AUTOSAR XML (schema 4-0-3)
package /PK_BB_Can_Network
  pdu Anchor1TpBle_A2M_Tp: length=64
  pdu Anchor1TpBle_M2A_Tp: length=64
  pdu Anchor2TpBle_A2M_Tp
  pdu Anchor3TpBle_A2M_Tp: length=64
  pdu Anchor4TpBle_A2M_Tp
  pdu Anchor5TpBle_A2M_Tp: length=64
  pdu Anchor6TpBle_A2M_Tp
  pdu Anchor7TpBle_A2M_Tp: length=64
  pdu Anchor8TpBle_A2M_Tp
  pdu Anchor9TpBle_A2M_Tp
  pdu Anchor{2..8}TpBle_M2A_Tp: length=64
  pdu Anchor9TpBle_M2A_Tp
  pdu Anchor{1..9}TpUwb_A2M_Tp: length=64
  pdu Anchor{1..9}TpUwb_M2A_Tp: length=64
  pdu TesterPhysical_Req_PK_Anchor{1..9}_Tp: length=64
  pdu TesterPhysical_Res_PK_Anchor{1..9}_Tp: length=64
  pdu TesterPhysical_Res_PK_MasterBle_Tp: length=64
  pdu TesterPhysical_Req_PK_MasterBle_Tp: length=64
  pdu TesterFunctional_Req_PK_Tp: length=64
  system PK_BB_Sys_Info
  i signal i pdu group MasterMcu_PK_BB_Rx: communication-direction=IN
    i-signal-i-pdus:
      Anchor{1..9}Hi_A2M
  i signal i pdu group MasterMcu_PK_BB_Tx: communication-direction=OUT, i-signal-i-pdus=MasterHi_M2A
package /PK_BB_Can_Network/Pkg_Cluster
  can cluster Can_Network_PK_BB: protocol-name=CAN
    can physical channel Can_Network_CHN_PK_BB: comm-connectors=Conn_Can_PK_BB_MasterEcu
      frame Anchor7Nm: id 0x477, to MasterMcu, frame-length=8, can-addressing-mode=STANDARD
        carries pdu Anchor7Nm: packing-byte-order=little-endian, start-position=0, update-indication-bit-position=-1
        nm pdu Anchor7Nm: length=8, nm-data-information=false, nm-vote-information=false
          signal WakeupReason_Anchor7: start 40, 8 bit, little-endian, base-type=uint8, to MasterMcu
          signal AutosarNMControlAnchor7: start 0, 8 bit, little-endian, init-value=0, base-type=uint8, compu {raw=phys for phys 0..255}, to MasterMcu  # SWS_CanNm_0045"
      frame Anchor6Nm: id 0x476, to MasterMcu, frame-length=8, can-addressing-mode=STANDARD
        carries pdu Anchor6Nm: packing-byte-order=little-endian, start-position=0, update-indication-bit-position=-1
        nm pdu Anchor6Nm: length=8, nm-data-information=false, nm-vote-information=false
          signal WakeupReason_Anchor6: start 40, 8 bit, little-endian, base-type=uint8, to MasterMcu
          signal AutosarNMControlAnchor6: start 0, 8 bit, little-endian, base-type=uint8, to MasterMcu  # SWS_CanNm_0045
      frame Anchor9TpBle_A2M: id 0x429, to MasterMcu, frame-length=64, can-addressing-mode=STANDARD
        carries pdu Anchor9TpBle_A2M: start-position=7, update-indication-bit-position=-1
        n pdu Anchor9TpBle_A2M: length=64
      frame Anchor8TpBle_A2M: id 0x428, to MasterMcu, frame-length=64, can-addressing-mode=STANDARD
        carries pdu Anchor8TpBle_A2M: start-position=7, update-indication-bit-position=-1
        n pdu Anchor8TpBle_A2M: length=64
      frame Anchor5Nm: id 0x475, to MasterMcu, frame-length=8, can-addressing-mode=STANDARD
        carries pdu Anchor5Nm: packing-byte-order=little-endian, start-position=0, update-indication-bit-position=-1
        nm pdu Anchor5Nm: length=8, nm-data-information=false, nm-vote-information=false
          signal WakeupReason_Anchor5: start 40, 8 bit, little-endian, base-type=uint8, to MasterMcu
          signal AutosarNMControlAnchor5: start 0, 8 bit, little-endian, base-type=uint8, to MasterMcu  # SWS_CanNm_0045
      frame Anchor4Nm: id 0x474, to MasterMcu, frame-length=8, can-addressing-mode=STANDARD
        carries pdu Anchor4Nm: packing-byte-order=little-endian, start-position=0, update-indication-bit-position=-1
        nm pdu Anchor4Nm: length=8, nm-data-information=false, nm-vote-information=false
          signal WakeupReason_Anchor4: start 40, 8 bit, little-endian, init-value=0, base-type=uint8, compu {raw=phys for phys 0..255, 0=NOWAKEUP, 1=NEWCONNECTIONREQUEST, 2=THRESHOLDCROSSED}, to MasterMcu
          signal AutosarNMControlAnchor4: start 0, 8 bit, little-endian, base-type=uint8, to MasterMcu  # SWS_CanNm_0045
      frame Anchor7TpBle_A2M: id 0x427, to MasterMcu, frame-length=64, can-addressing-mode=STANDARD
        carries pdu Anchor7TpBle_A2M: start-position=7, update-indication-bit-position=-1
        n pdu Anchor7TpBle_A2M: length=64
      frame Anchor6TpBle_A2M: id 0x426, to MasterMcu, frame-length=64, can-addressing-mode=STANDARD
        carries pdu Anchor6TpBle_A2M: start-position=7, update-indication-bit-position=-1
        n pdu Anchor6TpBle_A2M: length=64
      frame Anchor5TpBle_A2M: id 0x425, to MasterMcu, frame-length=64, can-addressing-mode=STANDARD
        carries pdu Anchor5TpBle_A2M: start-position=7, update-indication-bit-position=-1
        n pdu Anchor5TpBle_A2M: length=64
      frame Anchor4TpBle_A2M: id 0x424, to MasterMcu, frame-length=64, can-addressing-mode=STANDARD
        carries pdu Anchor4TpBle_A2M: start-position=7, update-indication-bit-position=-1
        n pdu Anchor4TpBle_A2M: length=64
      frame MasterBleXcpRequest: id 0x600, to MasterMcu, frame-length=8, can-addressing-mode=STANDARD
        carries pdu MasterBleXcpRequest: packing-byte-order=big-endian, start-position=7, update-indication-bit-position=-1
        pdu MasterBleXcpRequest: length=8, transmission-mode-condition{data-filter={data-filter-type=NEW-IS-WITHIN, max=2, min=0, offset=0}, i-signal-in-i-pdu=MasterBleXcpRequest}
          signal MasterBleXcpRequest: start 7, 64 bit, big-endian, base-type=uint64
      frame Anchor1Hi_A2M: id 0x161, to MasterMcu, frame-length=64, can-addressing-mode=STANDARD
        carries pdu Anchor1Hi_A2M: packing-byte-order=little-endian, start-position=0, update-indication-bit-position=-1
        pdu Anchor1Hi_A2M: length=64, transmission-mode-condition{data-filter={data-filter-type=NEW-IS-WITHIN, max=0, min=0, offset=0}, i-signal-in-i-pdu=Anchor1Hi_A2M_Payload}, transmission-mode-false-timing=cyclic-timing=time-period=0.1, transmission-mode-true-timing=cyclic-timing=time-period=0.1
          signal Anchor1Hi_A2M_Payload: start 0, 16 bit, little-endian, base-type=sint16, to MasterMcu
      frame Anchor3Nm: id 0x473, to MasterMcu, frame-length=8, can-addressing-mode=STANDARD
        carries pdu Anchor3Nm: packing-byte-order=little-endian, start-position=0, update-indication-bit-position=-1
        nm pdu Anchor3Nm: length=8, nm-data-information=false, nm-vote-information=false
          signal WakeupReason_Anchor3: start 40, 8 bit, little-endian, base-type=uint8, to MasterMcu
          signal AutosarNMControlAnchor3: start 0, 8 bit, little-endian, base-type=uint8, to MasterMcu  # SWS_CanNm_0045
      frame Anchor2Hi_A2M: id 0x162, to MasterMcu, frame-length=64, can-addressing-mode=STANDARD
        carries pdu Anchor2Hi_A2M: packing-byte-order=little-endian, start-position=0, update-indication-bit-position=-1
        pdu Anchor2Hi_A2M: length=64, transmission-mode-condition{data-filter={data-filter-type=NEW-IS-WITHIN, max=0, min=0, offset=0}, i-signal-in-i-pdu=Anchor2Hi_A2M_Payload}, transmission-mode-false-timing=cyclic-timing=time-period=0.1, transmission-mode-true-timing=cyclic-timing=time-period=0.1
          signal Anchor2Hi_A2M_Payload: start 0, 16 bit, little-endian, base-type=sint16, to MasterMcu
      frame Anchor2Nm: id 0x472, to MasterMcu, frame-length=8, can-addressing-mode=STANDARD
        carries pdu Anchor2Nm: packing-byte-order=little-endian, start-position=0, update-indication-bit-position=-1
        nm pdu Anchor2Nm: length=8, nm-data-information=false, nm-vote-information=false
          signal WakeupReason_Anchor2: start 40, 8 bit, little-endian, base-type=uint8, to MasterMcu
          signal AutosarNMControlAnchor2: start 0, 8 bit, little-endian, base-type=uint8, to MasterMcu  # SWS_CanNm_0045
      frame Anchor1Nm: id 0x471, to MasterMcu, frame-length=8, can-addressing-mode=STANDARD
        carries pdu Anchor1Nm: packing-byte-order=little-endian, start-position=0, update-indication-bit-position=-1
        nm pdu Anchor1Nm: length=8, nm-data-information=false, nm-vote-information=false
          signal WakeupReason_Anchor1: start 40, 8 bit, little-endian, init-value=0, base-type=uint8, compu {raw=phys for phys 0..255, 0=NOWAKEUP, 1=NEWCONNECTIONREQUEST, 2=THRESHOLDCROSSED}, to MasterMcu
          signal AutosarNMControlAnchor1: start 0, 8 bit, little-endian, base-type=uint8, to MasterMcu  # SWS_CanNm_0045
      frame Anchor3Hi_A2M: id 0x163, to MasterMcu, frame-length=64, can-addressing-mode=STANDARD
        carries pdu Anchor3Hi_A2M: packing-byte-order=little-endian, start-position=0, update-indication-bit-position=-1
        pdu Anchor3Hi_A2M: length=64, transmission-mode-condition{data-filter={data-filter-type=NEW-IS-WITHIN, max=0, min=0, offset=0}, i-signal-in-i-pdu=Anchor3Hi_A2M_Payload}, transmission-mode-false-timing=cyclic-timing=time-period=0.1, transmission-mode-true-timing=cyclic-timing=time-period=0.1
          signal Anchor3Hi_A2M_Payload: start 0, 16 bit, little-endian, init-value=0, base-type=sint16, compu {raw=phys for phys 0}, to MasterMcu
      frame Anchor3TpBle_A2M: id 0x423, to MasterMcu, frame-length=64, can-addressing-mode=STANDARD
        carries pdu Anchor3TpBle_A2M: start-position=7, update-indication-bit-position=-1
        n pdu Anchor3TpBle_A2M: length=64
      frame Anchor4Hi_A2M: id 0x164, to MasterMcu, frame-length=64, can-addressing-mode=STANDARD
        carries pdu Anchor4Hi_A2M: packing-byte-order=little-endian, start-position=0, update-indication-bit-position=-1
        pdu Anchor4Hi_A2M: length=64, transmission-mode-condition{data-filter={data-filter-type=NEW-IS-WITHIN, max=0, min=0, offset=0}, i-signal-in-i-pdu=Anchor4Hi_A2M_Payload}
          signal Anchor4Hi_A2M_Payload: start 0, 16 bit, little-endian, base-type=sint16, to MasterMcu
      frame Anchor2TpBle_A2M: id 0x422, to MasterMcu, frame-length=64, can-addressing-mode=STANDARD
        carries pdu Anchor2TpBle_A2M: start-position=7, update-indication-bit-position=-1
        n pdu Anchor2TpBle_A2M: length=64
      frame Anchor5Hi_A2M: id 0x165, to MasterMcu, frame-length=64, can-addressing-mode=STANDARD
        carries pdu Anchor5Hi_A2M: packing-byte-order=little-endian, start-position=0, update-indication-bit-position=-1
        pdu Anchor5Hi_A2M: length=64, transmission-mode-condition{data-filter={data-filter-type=NEW-IS-WITHIN, max=0, min=0, offset=0}, i-signal-in-i-pdu=Anchor5Hi_A2M_Payload}
          signal Anchor5Hi_A2M_Payload: start 0, 16 bit, little-endian, init-value=0, base-type=sint16, compu {raw=phys for phys 0}, to MasterMcu
      frame Anchor1TpBle_A2M: id 0x421, to MasterMcu, frame-length=64, can-addressing-mode=STANDARD
        carries pdu Anchor1TpBle_A2M: start-position=7, update-indication-bit-position=-1
        n pdu Anchor1TpBle_A2M: length=64
      frame Anchor6Hi_A2M: id 0x166, to MasterMcu, frame-length=64, can-addressing-mode=STANDARD
        carries pdu Anchor6Hi_A2M: packing-byte-order=little-endian, start-position=0, update-indication-bit-position=-1
        pdu Anchor6Hi_A2M: length=64, transmission-mode-condition{data-filter={data-filter-type=NEW-IS-WITHIN, max=0, min=0, offset=0}, i-signal-in-i-pdu=Anchor6Hi_A2M_Payload}
          signal Anchor6Hi_A2M_Payload: start 0, 16 bit, little-endian, init-value=0, base-type=sint16, compu {raw=phys for phys 0}, to MasterMcu
      frame Anchor7Hi_A2M: id 0x167, to MasterMcu, frame-length=64, can-addressing-mode=STANDARD
        carries pdu Anchor7Hi_A2M: packing-byte-order=little-endian, start-position=0, update-indication-bit-position=-1
        pdu Anchor7Hi_A2M: length=64, transmission-mode-condition{data-filter={data-filter-type=NEW-IS-WITHIN, max=0, min=0, offset=0}, i-signal-in-i-pdu=Anchor7Hi_A2M_Payload}, transmission-mode-false-timing=cyclic-timing=time-period=0.1, transmission-mode-true-timing=cyclic-timing=time-period=0.1
          signal Anchor7Hi_A2M_Payload: start 0, 16 bit, little-endian, base-type=sint16, to MasterMcu
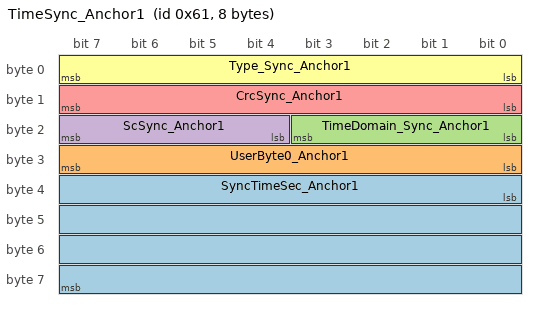
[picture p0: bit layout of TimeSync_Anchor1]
      frame TimeSync_Anchor1: id 0x61, to MasterMcu, frame-length=8, can-addressing-mode=STANDARD
        carries pdu TimeSync_Anchor1: packing-byte-order=little-endian, start-position=0, update-indication-bit-position=-1
        pdu TimeSync_Anchor1: length=8, transmission-mode-false-timing=cyclic-timing={time-offset=0.0, time-period=5.0}, transmission-mode-true-timing=cyclic-timing={time-offset=0.0, time-period=5.0}
          transmission-mode-conditions:
            {data-filter={data-filter-type=NEW-IS-WITHIN, max=4294967295, min=0, offset=0}, i-signal-in-i-pdu=SyncTimeSec_Anchor1}
            {data-filter={data-filter-type=ALWAYS, max=255, min=0, offset=0}, i-signal-in-i-pdu=UserByte0_Anchor1}
            {data-filter={data-filter-type=ALWAYS, max=15, min=0, offset=0}, i-signal-in-i-pdu=TimeDomain_Sync_Anchor1}
            {data-filter={data-filter-type=ALWAYS, max=15, min=0, offset=0}, i-signal-in-i-pdu=ScSync_Anchor1}
            {data-filter={data-filter-type=ALWAYS, max=255, min=0, offset=0}, i-signal-in-i-pdu=CrcSync_Anchor1}
            {data-filter={data-filter-type=ALWAYS, max=255, min=0, offset=0}, i-signal-in-i-pdu=Type_Sync_Anchor1}
          signal SyncTimeSec_Anchor1: start 32, 32 bit, little-endian, base-type=uint32, to MasterMcu
          signal UserByte0_Anchor1: start 24, 8 bit, little-endian, base-type=uint8, to MasterMcu
          signal TimeDomain_Sync_Anchor1: start 16, 4 bit, little-endian, base-type=uint8, to MasterMcu
          signal ScSync_Anchor1: start 20, 4 bit, little-endian, base-type=uint8, to MasterMcu
          signal CrcSync_Anchor1: start 8, 8 bit, little-endian, base-type=uint8, to MasterMcu
          signal Type_Sync_Anchor1: start 0, 8 bit, little-endian, init-value=32, base-type=uint8, compu {raw=phys for phys 0..255}, to MasterMcu
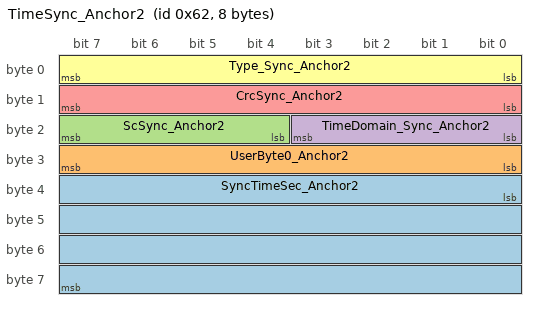
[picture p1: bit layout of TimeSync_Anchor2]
      frame TimeSync_Anchor2: id 0x62, to MasterMcu, frame-length=8, can-addressing-mode=STANDARD
        carries pdu TimeSync_Anchor2: packing-byte-order=little-endian, start-position=0, update-indication-bit-position=-1
        pdu TimeSync_Anchor2: length=8, transmission-mode-false-timing=cyclic-timing={time-offset=0.0, time-period=5.0}, transmission-mode-true-timing=cyclic-timing={time-offset=0.0, time-period=5.0}
          transmission-mode-conditions:
            {data-filter={data-filter-type=NEW-IS-WITHIN, max=4294967295, min=0, offset=0}, i-signal-in-i-pdu=SyncTimeSec_Anchor2}
            {data-filter={data-filter-type=ALWAYS, max=255, min=0, offset=0}, i-signal-in-i-pdu=UserByte0_Anchor2}
            {data-filter={data-filter-type=ALWAYS, max=15, min=0, offset=0}, i-signal-in-i-pdu=ScSync_Anchor2}
            {data-filter={data-filter-type=ALWAYS, max=15, min=0, offset=0}, i-signal-in-i-pdu=TimeDomain_Sync_Anchor2}
            {data-filter={data-filter-type=ALWAYS, max=255, min=0, offset=0}, i-signal-in-i-pdu=CrcSync_Anchor2}
            {data-filter={data-filter-type=ALWAYS, max=255, min=0, offset=0}, i-signal-in-i-pdu=Type_Sync_Anchor2}
          signal SyncTimeSec_Anchor2: start 32, 32 bit, little-endian, init-value=0, base-type=uint32, compu {raw=phys for phys 0..4294967295}, to MasterMcu
          signal UserByte0_Anchor2: start 24, 8 bit, little-endian, init-value=0, base-type=uint8, compu {raw=phys for phys 0..255}, to MasterMcu
          signal ScSync_Anchor2: start 20, 4 bit, little-endian, base-type=uint8, to MasterMcu
          signal TimeDomain_Sync_Anchor2: start 16, 4 bit, little-endian, base-type=uint8, to MasterMcu
          signal CrcSync_Anchor2: start 8, 8 bit, little-endian, init-value=0, base-type=uint8, compu {raw=phys for phys 0..255}, to MasterMcu
          signal Type_Sync_Anchor2: start 0, 8 bit, little-endian, base-type=uint8, to MasterMcu
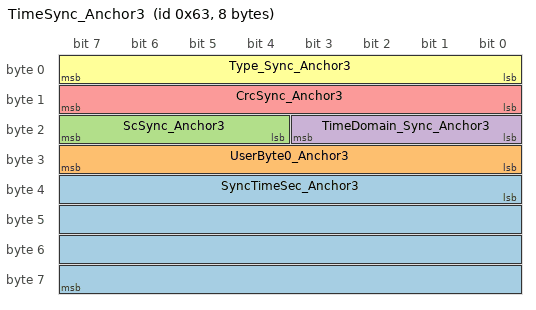
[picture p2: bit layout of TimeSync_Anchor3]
      frame TimeSync_Anchor3: id 0x63, to MasterMcu, frame-length=8, can-addressing-mode=STANDARD
        carries pdu TimeSync_Anchor3: packing-byte-order=little-endian, start-position=0, update-indication-bit-position=-1
        pdu TimeSync_Anchor3: length=8, transmission-mode-false-timing=cyclic-timing={time-offset=0.0, time-period=5.0}, transmission-mode-true-timing=cyclic-timing={time-offset=0.0, time-period=5.0}
          transmission-mode-conditions:
            {data-filter={data-filter-type=NEW-IS-WITHIN, max=4294967295, min=0, offset=0}, i-signal-in-i-pdu=SyncTimeSec_Anchor3}
            {data-filter={data-filter-type=ALWAYS, max=255, min=0, offset=0}, i-signal-in-i-pdu=UserByte0_Anchor3}
            {data-filter={data-filter-type=ALWAYS, max=15, min=0, offset=0}, i-signal-in-i-pdu=ScSync_Anchor3}
            {data-filter={data-filter-type=ALWAYS, max=15, min=0, offset=0}, i-signal-in-i-pdu=TimeDomain_Sync_Anchor3}
            {data-filter={data-filter-type=ALWAYS, max=255, min=0, offset=0}, i-signal-in-i-pdu=CrcSync_Anchor3}
            {data-filter={data-filter-type=ALWAYS, max=255, min=0, offset=0}, i-signal-in-i-pdu=Type_Sync_Anchor3}
          signal SyncTimeSec_Anchor3: start 32, 32 bit, little-endian, base-type=uint32, to MasterMcu
          signal UserByte0_Anchor3: start 24, 8 bit, little-endian, base-type=uint8, to MasterMcu
          signal ScSync_Anchor3: start 20, 4 bit, little-endian, init-value=0, base-type=uint8, compu {raw=phys for phys 0..15}, to MasterMcu
          signal TimeDomain_Sync_Anchor3: start 16, 4 bit, little-endian, base-type=uint8, to MasterMcu
          signal CrcSync_Anchor3: start 8, 8 bit, little-endian, base-type=uint8, to MasterMcu
          signal Type_Sync_Anchor3: start 0, 8 bit, little-endian, base-type=uint8, to MasterMcu
      frame TesterPhysical_Req_PK_MasterBle: id 0x700, to MasterMcu, frame-length=64, can-addressing-mode=STANDARD
        carries pdu TesterPhysical_Req_PK_MasterBle: start-position=7, update-indication-bit-position=-1
        n pdu TesterPhysical_Req_PK_MasterBle: length=64
      frame Anchor8Hi_A2M: id 0x168, to MasterMcu, frame-length=64, can-addressing-mode=STANDARD
        carries pdu Anchor8Hi_A2M: packing-byte-order=little-endian, start-position=0, update-indication-bit-position=-1
        pdu Anchor8Hi_A2M: length=64, transmission-mode-condition{data-filter={data-filter-type=NEW-IS-WITHIN, max=0, min=0, offset=0}, i-signal-in-i-pdu=Anchor8Hi_A2M_Payload}
          signal Anchor8Hi_A2M_Payload: start 0, 16 bit, little-endian, base-type=sint16, to MasterMcu
      frame Anchor9Hi_A2M: id 0x169, to MasterMcu, frame-length=64, can-addressing-mode=STANDARD
        carries pdu Anchor9Hi_A2M: packing-byte-order=little-endian, start-position=0, update-indication-bit-position=-1
        pdu Anchor9Hi_A2M: length=64, transmission-mode-condition{data-filter={data-filter-type=NEW-IS-WITHIN, max=0, min=0, offset=0}, i-signal-in-i-pdu=Anchor9Hi_A2M_Payload}, transmission-mode-false-timing=cyclic-timing=time-period=0.1, transmission-mode-true-timing=cyclic-timing=time-period=0.1
          signal Anchor9Hi_A2M_Payload: start 0, 16 bit, little-endian, base-type=sint16, to MasterMcu
      frame Anchor9Nm: id 0x479, to MasterMcu, frame-length=8, can-addressing-mode=STANDARD
        carries pdu Anchor9Nm: packing-byte-order=little-endian, start-position=0, update-indication-bit-position=-1
        nm pdu Anchor9Nm: length=8, nm-data-information=false, nm-vote-information=false
          signal WakeupReason_Anchor9: start 40, 8 bit, little-endian, init-value=0, base-type=uint8, compu {raw=phys for phys 0..255, 0=NOWAKEUP, 1=NEWCONNECTIONREQUEST, 2=THRESHOLDCROSSED}, to MasterMcu
          signal AutosarNMControlAnchor9: start 0, 8 bit, little-endian, base-type=uint8, to MasterMcu  # SWS_CanNm_0045
      frame Anchor8Nm: id 0x478, to MasterMcu, frame-length=8, can-addressing-mode=STANDARD
        carries pdu Anchor8Nm: packing-byte-order=little-endian, start-position=0, update-indication-bit-position=-1
        nm pdu Anchor8Nm: length=8, nm-data-information=false, nm-vote-information=false
          signal WakeupReason_Anchor8: start 40, 8 bit, little-endian, base-type=uint8, to MasterMcu
          signal AutosarNMControlAnchor8: start 0, 8 bit, little-endian, init-value=0, base-type=uint8, compu {raw=phys for phys 0..255}, to MasterMcu  # SWS_CanNm_0045"
      frame TesterPhysical_Res_PK_Anchor5: id 0x725, to MasterMcu, frame-length=64, can-addressing-mode=STANDARD
        carries pdu TesterPhysical_Res_PK_Anchor5: start-position=7, update-indication-bit-position=-1
        n pdu TesterPhysical_Res_PK_Anchor5: length=64
      frame TesterPhysical_Res_PK_Anchor4: id 0x724, to MasterMcu, frame-length=64, can-addressing-mode=STANDARD
        carries pdu TesterPhysical_Res_PK_Anchor4: start-position=7, update-indication-bit-position=-1
        n pdu TesterPhysical_Res_PK_Anchor4: length=64
      frame TesterPhysical_Res_PK_Anchor3: id 0x723, to MasterMcu, frame-length=64, can-addressing-mode=STANDARD
        carries pdu TesterPhysical_Res_PK_Anchor3: start-position=7, update-indication-bit-position=-1
        n pdu TesterPhysical_Res_PK_Anchor3: length=64
      frame TesterPhysical_Res_PK_Anchor2: id 0x722, to MasterMcu, frame-length=64, can-addressing-mode=STANDARD
        carries pdu TesterPhysical_Res_PK_Anchor2: start-position=7, update-indication-bit-position=-1
        n pdu TesterPhysical_Res_PK_Anchor2: length=64
      frame TesterPhysical_Res_PK_Anchor1: id 0x721, to MasterMcu, frame-length=64, can-addressing-mode=STANDARD
        carries pdu TesterPhysical_Res_PK_Anchor1: start-position=7, update-indication-bit-position=-1
        n pdu TesterPhysical_Res_PK_Anchor1: length=64
      frame Anchor1TpUwb_A2M: id 0x461, to MasterMcu, frame-length=64, can-addressing-mode=STANDARD
        carries pdu Anchor1TpUwb_A2M: start-position=7, update-indication-bit-position=-1
        n pdu Anchor1TpUwb_A2M: length=64
      frame TesterPhysical_Res_PK_Anchor9: id 0x729, to MasterMcu, frame-length=64, can-addressing-mode=STANDARD
        carries pdu TesterPhysical_Res_PK_Anchor9: start-position=7, update-indication-bit-position=-1
        n pdu TesterPhysical_Res_PK_Anchor9: length=64
      frame TesterPhysical_Res_PK_Anchor8: id 0x728, to MasterMcu, frame-length=64, can-addressing-mode=STANDARD
        carries pdu TesterPhysical_Res_PK_Anchor8: start-position=7, update-indication-bit-position=-1
        n pdu TesterPhysical_Res_PK_Anchor8: length=64
      frame TesterPhysical_Res_PK_Anchor7: id 0x727, to MasterMcu, frame-length=64, can-addressing-mode=STANDARD
        carries pdu TesterPhysical_Res_PK_Anchor7: start-position=7, update-indication-bit-position=-1
        n pdu TesterPhysical_Res_PK_Anchor7: length=64
      frame TesterPhysical_Res_PK_Anchor6: id 0x726, to MasterMcu, frame-length=64, can-addressing-mode=STANDARD
        carries pdu TesterPhysical_Res_PK_Anchor6: start-position=7, update-indication-bit-position=-1
        n pdu TesterPhysical_Res_PK_Anchor6: length=64
      frame Anchor9TpUwb_A2M: id 0x469, to MasterMcu, frame-length=64, can-addressing-mode=STANDARD
        carries pdu Anchor9TpUwb_A2M: start-position=7, update-indication-bit-position=-1
        n pdu Anchor9TpUwb_A2M: length=64
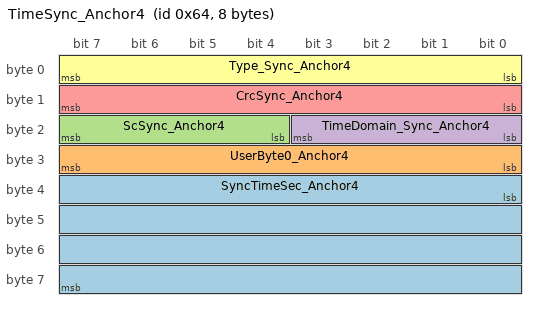
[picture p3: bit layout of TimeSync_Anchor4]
      frame TimeSync_Anchor4: id 0x64, to MasterMcu, frame-length=8, can-addressing-mode=STANDARD
        carries pdu TimeSync_Anchor4: packing-byte-order=little-endian, start-position=0, update-indication-bit-position=-1
        pdu TimeSync_Anchor4: length=8, transmission-mode-false-timing=cyclic-timing={time-offset=0.0, time-period=5.0}, transmission-mode-true-timing=cyclic-timing={time-offset=0.0, time-period=5.0}
          transmission-mode-conditions:
            {data-filter={data-filter-type=NEW-IS-WITHIN, max=4294967295, min=0, offset=0}, i-signal-in-i-pdu=SyncTimeSec_Anchor4}
            {data-filter={data-filter-type=ALWAYS, max=255, min=0, offset=0}, i-signal-in-i-pdu=UserByte0_Anchor4}
            {data-filter={data-filter-type=ALWAYS, max=15, min=0, offset=0}, i-signal-in-i-pdu=ScSync_Anchor4}
            {data-filter={data-filter-type=ALWAYS, max=15, min=0, offset=0}, i-signal-in-i-pdu=TimeDomain_Sync_Anchor4}
            {data-filter={data-filter-type=ALWAYS, max=255, min=0, offset=0}, i-signal-in-i-pdu=CrcSync_Anchor4}
            {data-filter={data-filter-type=ALWAYS, max=255, min=0, offset=0}, i-signal-in-i-pdu=Type_Sync_Anchor4}
          signal SyncTimeSec_Anchor4: start 32, 32 bit, little-endian, base-type=uint32, to MasterMcu
          signal UserByte0_Anchor4: start 24, 8 bit, little-endian, base-type=uint8, to MasterMcu
          signal ScSync_Anchor4: start 20, 4 bit, little-endian, base-type=uint8, to MasterMcu
          signal TimeDomain_Sync_Anchor4: start 16, 4 bit, little-endian, base-type=uint8, to MasterMcu
          signal CrcSync_Anchor4: start 8, 8 bit, little-endian, base-type=uint8, to MasterMcu
          signal Type_Sync_Anchor4: start 0, 8 bit, little-endian, base-type=uint8, to MasterMcu
      frame Anchor8TpUwb_A2M: id 0x468, to MasterMcu, frame-length=64, can-addressing-mode=STANDARD
        carries pdu Anchor8TpUwb_A2M: start-position=7, update-indication-bit-position=-1
        n pdu Anchor8TpUwb_A2M: length=64
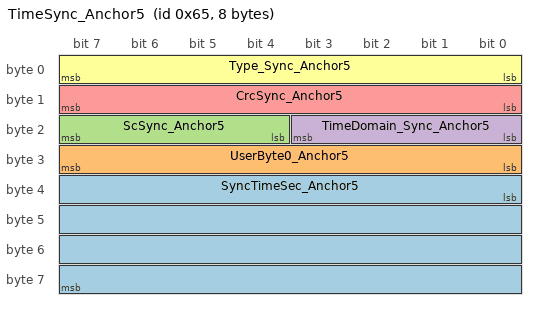
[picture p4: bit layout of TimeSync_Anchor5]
      frame TimeSync_Anchor5: id 0x65, to MasterMcu, frame-length=8, can-addressing-mode=STANDARD
        carries pdu TimeSync_Anchor5: packing-byte-order=little-endian, start-position=0, update-indication-bit-position=-1
        pdu TimeSync_Anchor5: length=8, transmission-mode-false-timing=cyclic-timing={time-offset=0.0, time-period=5.0}, transmission-mode-true-timing=cyclic-timing={time-offset=0.0, time-period=5.0}
          transmission-mode-conditions:
            {data-filter={data-filter-type=NEW-IS-WITHIN, max=4294967295, min=0, offset=0}, i-signal-in-i-pdu=SyncTimeSec_Anchor5}
            {data-filter={data-filter-type=ALWAYS, max=255, min=0, offset=0}, i-signal-in-i-pdu=UserByte0_Anchor5}
            {data-filter={data-filter-type=ALWAYS, max=15, min=0, offset=0}, i-signal-in-i-pdu=ScSync_Anchor5}
            {data-filter={data-filter-type=ALWAYS, max=15, min=0, offset=0}, i-signal-in-i-pdu=TimeDomain_Sync_Anchor5}
            {data-filter={data-filter-type=ALWAYS, max=255, min=0, offset=0}, i-signal-in-i-pdu=CrcSync_Anchor5}
            {data-filter={data-filter-type=ALWAYS, max=255, min=0, offset=0}, i-signal-in-i-pdu=Type_Sync_Anchor5}
          signal SyncTimeSec_Anchor5: start 32, 32 bit, little-endian, base-type=uint32, to MasterMcu
          signal UserByte0_Anchor5: start 24, 8 bit, little-endian, base-type=uint8, to MasterMcu
          signal ScSync_Anchor5: start 20, 4 bit, little-endian, init-value=0, base-type=uint8, compu {raw=phys for phys 0..15}, to MasterMcu
          signal TimeDomain_Sync_Anchor5: start 16, 4 bit, little-endian, base-type=uint8, to MasterMcu
          signal CrcSync_Anchor5: start 8, 8 bit, little-endian, base-type=uint8, to MasterMcu
          signal Type_Sync_Anchor5: start 0, 8 bit, little-endian, init-value=0, base-type=uint8, compu {raw=phys for phys 0..255}, to MasterMcu
      frame MasterUwbXcpRequest: id 0x640, to MasterMcu, frame-length=8, can-addressing-mode=STANDARD
        carries pdu MasterUwbXcpRequest: packing-byte-order=big-endian, start-position=7, update-indication-bit-position=-1
        pdu MasterUwbXcpRequest: length=8, transmission-mode-condition{data-filter={data-filter-type=NEW-IS-WITHIN, max=2, min=0, offset=0}, i-signal-in-i-pdu=MasterUwbXcpRequest}
          signal MasterUwbXcpRequest: start 7, 64 bit, big-endian, init-value=0, base-type=uint64, compu {raw=phys for phys 0..1.8446744}
      frame Anchor7TpUwb_A2M: id 0x467, to MasterMcu, frame-length=64, can-addressing-mode=STANDARD
        carries pdu Anchor7TpUwb_A2M: start-position=7, update-indication-bit-position=-1
        n pdu Anchor7TpUwb_A2M: length=64
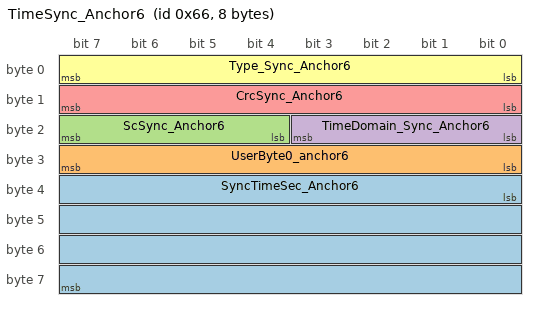
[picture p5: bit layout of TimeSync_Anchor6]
      frame TimeSync_Anchor6: id 0x66, to MasterMcu, frame-length=8, can-addressing-mode=STANDARD
        carries pdu TimeSync_Anchor6: packing-byte-order=little-endian, start-position=0, update-indication-bit-position=-1
        pdu TimeSync_Anchor6: length=8, transmission-mode-false-timing=cyclic-timing={time-offset=0.0, time-period=5.0}, transmission-mode-true-timing=cyclic-timing={time-offset=0.0, time-period=5.0}
          transmission-mode-conditions:
            {data-filter={data-filter-type=NEW-IS-WITHIN, max=4294967295, min=0, offset=0}, i-signal-in-i-pdu=SyncTimeSec_Anchor6}
            {data-filter={data-filter-type=ALWAYS, max=255, min=0, offset=0}, i-signal-in-i-pdu=UserByte0_anchor6}
            {data-filter={data-filter-type=ALWAYS, max=15, min=0, offset=0}, i-signal-in-i-pdu=ScSync_Anchor6}
            {data-filter={data-filter-type=ALWAYS, max=15, min=0, offset=0}, i-signal-in-i-pdu=TimeDomain_Sync_Anchor6}
            {data-filter={data-filter-type=ALWAYS, max=255, min=0, offset=0}, i-signal-in-i-pdu=CrcSync_Anchor6}
            {data-filter={data-filter-type=ALWAYS, max=255, min=0, offset=0}, i-signal-in-i-pdu=Type_Sync_Anchor6}
          signal SyncTimeSec_Anchor6: start 32, 32 bit, little-endian, base-type=uint32, to MasterMcu
          signal UserByte0_anchor6: start 24, 8 bit, little-endian, base-type=uint8, to MasterMcu
          signal ScSync_Anchor6: start 20, 4 bit, little-endian, init-value=0, base-type=uint8, compu {raw=phys for phys 0..15}, to MasterMcu
          signal TimeDomain_Sync_Anchor6: start 16, 4 bit, little-endian, init-value=0, base-type=uint8, compu {raw=phys for phys 0..15}, to MasterMcu
          signal CrcSync_Anchor6: start 8, 8 bit, little-endian, base-type=uint8, to MasterMcu
          signal Type_Sync_Anchor6: start 0, 8 bit, little-endian, base-type=uint8, to MasterMcu
      frame Anchor6TpUwb_A2M: id 0x466, to MasterMcu, frame-length=64, can-addressing-mode=STANDARD
        carries pdu Anchor6TpUwb_A2M: start-position=7, update-indication-bit-position=-1
        n pdu Anchor6TpUwb_A2M: length=64
      frame Anchor5TpUwb_A2M: id 0x465, to MasterMcu, frame-length=64, can-addressing-mode=STANDARD
        carries pdu Anchor5TpUwb_A2M: start-position=7, update-indication-bit-position=-1
        n pdu Anchor5TpUwb_A2M: length=64
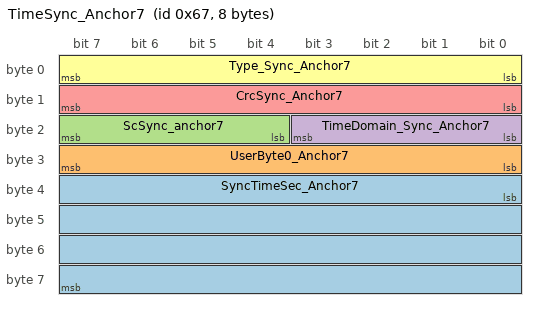
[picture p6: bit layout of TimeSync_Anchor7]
      frame TimeSync_Anchor7: id 0x67, to MasterMcu, frame-length=8, can-addressing-mode=STANDARD
        carries pdu TimeSync_Anchor7: packing-byte-order=little-endian, start-position=0, update-indication-bit-position=-1
        pdu TimeSync_Anchor7: length=8, transmission-mode-false-timing=cyclic-timing={time-offset=0.0, time-period=5.0}, transmission-mode-true-timing=cyclic-timing={time-offset=0.0, time-period=5.0}
          transmission-mode-conditions:
            {data-filter={data-filter-type=NEW-IS-WITHIN, max=4294967295, min=0, offset=0}, i-signal-in-i-pdu=SyncTimeSec_Anchor7}
            {data-filter={data-filter-type=ALWAYS, max=255, min=0, offset=0}, i-signal-in-i-pdu=UserByte0_Anchor7}
            {data-filter={data-filter-type=ALWAYS, max=15, min=0, offset=0}, i-signal-in-i-pdu=ScSync_anchor7}
            {data-filter={data-filter-type=ALWAYS, max=15, min=0, offset=0}, i-signal-in-i-pdu=TimeDomain_Sync_Anchor7}
            {data-filter={data-filter-type=ALWAYS, max=255, min=0, offset=0}, i-signal-in-i-pdu=CrcSync_Anchor7}
            {data-filter={data-filter-type=ALWAYS, max=255, min=0, offset=0}, i-signal-in-i-pdu=Type_Sync_Anchor7}
          signal SyncTimeSec_Anchor7: start 32, 32 bit, little-endian, base-type=uint32, to MasterMcu
          signal UserByte0_Anchor7: start 24, 8 bit, little-endian, init-value=0, base-type=uint8, compu {raw=phys for phys 0..255}, to MasterMcu
          signal ScSync_anchor7: start 20, 4 bit, little-endian, base-type=uint8, to MasterMcu
          signal TimeDomain_Sync_Anchor7: start 16, 4 bit, little-endian, init-value=0, base-type=uint8, compu {raw=phys for phys 0..15}, to MasterMcu
          signal CrcSync_Anchor7: start 8, 8 bit, little-endian, base-type=uint8, to MasterMcu
          signal Type_Sync_Anchor7: start 0, 8 bit, little-endian, init-value=32, base-type=uint8, compu {raw=phys for phys 0..255}, to MasterMcu
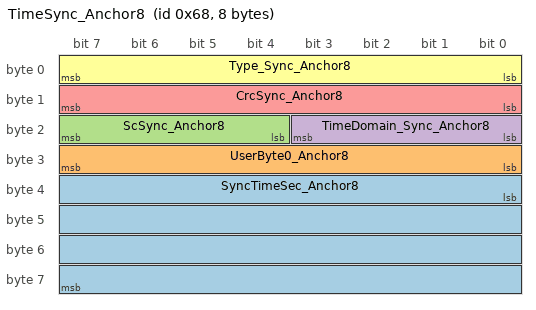
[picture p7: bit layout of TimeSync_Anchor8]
      frame TimeSync_Anchor8: id 0x68, to MasterMcu, frame-length=8, can-addressing-mode=STANDARD
        carries pdu TimeSync_Anchor8: packing-byte-order=little-endian, start-position=0, update-indication-bit-position=-1
        pdu TimeSync_Anchor8: length=8, transmission-mode-false-timing=cyclic-timing={time-offset=0.0, time-period=5.0}, transmission-mode-true-timing=cyclic-timing={time-offset=0.0, time-period=5.0}
          transmission-mode-conditions:
            {data-filter={data-filter-type=NEW-IS-WITHIN, max=4294967295, min=0, offset=0}, i-signal-in-i-pdu=SyncTimeSec_Anchor8}
            {data-filter={data-filter-type=ALWAYS, max=255, min=0, offset=0}, i-signal-in-i-pdu=UserByte0_Anchor8}
            {data-filter={data-filter-type=ALWAYS, max=15, min=0, offset=0}, i-signal-in-i-pdu=TimeSync_Anchor8/ScSync_Anchor8}
            {data-filter={data-filter-type=ALWAYS, max=15, min=0, offset=0}, i-signal-in-i-pdu=TimeDomain_Sync_Anchor8}
            {data-filter={data-filter-type=ALWAYS, max=255, min=0, offset=0}, i-signal-in-i-pdu=CrcSync_Anchor8}
            {data-filter={data-filter-type=ALWAYS, max=255, min=0, offset=0}, i-signal-in-i-pdu=Type_Sync_Anchor8}
          signal SyncTimeSec_Anchor8: start 32, 32 bit, little-endian, base-type=uint32, to MasterMcu
          signal UserByte0_Anchor8: start 24, 8 bit, little-endian, base-type=uint8, to MasterMcu
          signal ScSync_Anchor8: start 20, 4 bit, little-endian, base-type=uint8, to MasterMcu
          signal TimeDomain_Sync_Anchor8: start 16, 4 bit, little-endian, init-value=0, base-type=uint8, compu {raw=phys for phys 0..15}, to MasterMcu
          signal CrcSync_Anchor8: start 8, 8 bit, little-endian, init-value=0, base-type=uint8, compu {raw=phys for phys 0..255}, to MasterMcu
          signal Type_Sync_Anchor8: start 0, 8 bit, little-endian, init-value=32, base-type=uint8, compu {raw=phys for phys 0..255}, to MasterMcu
      frame Anchor4TpUwb_A2M: id 0x464, to MasterMcu, frame-length=64, can-addressing-mode=STANDARD
        carries pdu Anchor4TpUwb_A2M: start-position=7, update-indication-bit-position=-1
        n pdu Anchor4TpUwb_A2M: length=64
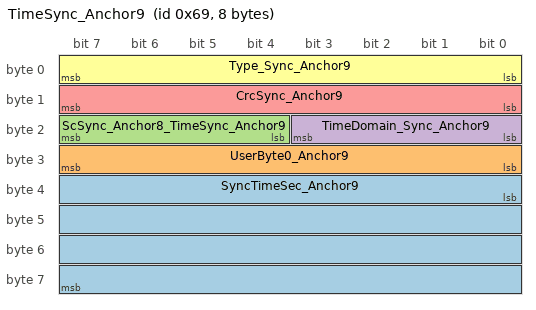
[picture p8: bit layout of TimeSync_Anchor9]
      frame TimeSync_Anchor9: id 0x69, to MasterMcu, frame-length=8, can-addressing-mode=STANDARD
        carries pdu TimeSync_Anchor9: packing-byte-order=little-endian, start-position=0, update-indication-bit-position=-1
        pdu TimeSync_Anchor9: length=8, transmission-mode-false-timing=cyclic-timing={time-offset=0.0, time-period=5.0}, transmission-mode-true-timing=cyclic-timing={time-offset=0.0, time-period=5.0}
          transmission-mode-conditions:
            {data-filter={data-filter-type=NEW-IS-WITHIN, max=4294967295, min=0, offset=0}, i-signal-in-i-pdu=SyncTimeSec_Anchor9}
            {data-filter={data-filter-type=ALWAYS, max=255, min=0, offset=0}, i-signal-in-i-pdu=UserByte0_Anchor9}
            {data-filter={data-filter-type=ALWAYS, max=15, min=0, offset=0}, i-signal-in-i-pdu=TimeSync_Anchor9/ScSync_Anchor8}
            {data-filter={data-filter-type=ALWAYS, max=15, min=0, offset=0}, i-signal-in-i-pdu=TimeDomain_Sync_Anchor9}
            {data-filter={data-filter-type=ALWAYS, max=255, min=0, offset=0}, i-signal-in-i-pdu=CrcSync_Anchor9}
            {data-filter={data-filter-type=ALWAYS, max=255, min=0, offset=0}, i-signal-in-i-pdu=Type_Sync_Anchor9}
          signal SyncTimeSec_Anchor9: start 32, 32 bit, little-endian, base-type=uint32, to MasterMcu
          signal UserByte0_Anchor9: start 24, 8 bit, little-endian, init-value=0, base-type=uint8, compu {raw=phys for phys 0..255}, to MasterMcu
          signal ScSync_Anchor8_TimeSync_Anchor9: start 20, 4 bit, little-endian, init-value=0, base-type=uint8, compu {raw=phys for phys 0..15}, to MasterMcu
          signal TimeDomain_Sync_Anchor9: start 16, 4 bit, little-endian, init-value=0, base-type=uint8, compu {raw=phys for phys 0..15}, to MasterMcu
          signal CrcSync_Anchor9: start 8, 8 bit, little-endian, init-value=0, base-type=uint8, compu {raw=phys for phys 0..255}, to MasterMcu
          signal Type_Sync_Anchor9: start 0, 8 bit, little-endian, base-type=uint8, to MasterMcu
      frame Anchor3TpUwb_A2M: id 0x463, to MasterMcu, frame-length=64, can-addressing-mode=STANDARD
        carries pdu Anchor3TpUwb_A2M: start-position=7, update-indication-bit-position=-1
        n pdu Anchor3TpUwb_A2M: length=64
      frame Anchor2TpUwb_A2M: id 0x462, to MasterMcu, frame-length=64, can-addressing-mode=STANDARD
        carries pdu Anchor2TpUwb_A2M: start-position=7, update-indication-bit-position=-1
        n pdu Anchor2TpUwb_A2M: length=64
      frame TesterPhysical_Req_PK_Anchor7: id 0x707, from MasterMcu, frame-length=64, can-addressing-mode=STANDARD
        carries pdu TesterPhysical_Req_PK_Anchor7: start-position=7, update-indication-bit-position=-1
        n pdu TesterPhysical_Req_PK_Anchor7: length=64
      frame TesterPhysical_Req_PK_Anchor6: id 0x706, from MasterMcu, frame-length=64, can-addressing-mode=STANDARD
        carries pdu TesterPhysical_Req_PK_Anchor6: start-position=7, update-indication-bit-position=-1
        n pdu TesterPhysical_Req_PK_Anchor6: length=64
      frame TesterPhysical_Req_PK_Anchor5: id 0x705, from MasterMcu, frame-length=64, can-addressing-mode=STANDARD
        carries pdu TesterPhysical_Req_PK_Anchor5: start-position=7, update-indication-bit-position=-1
        n pdu TesterPhysical_Req_PK_Anchor5: length=64
      frame MasterUwbXcpResponse: id 0x660, from MasterMcu, frame-length=8, can-addressing-mode=STANDARD
        carries pdu MasterUwbXcpResponse: packing-byte-order=big-endian, start-position=7, update-indication-bit-position=-1
        pdu MasterUwbXcpResponse: length=8, transmission-mode-condition{data-filter={data-filter-type=NEW-IS-WITHIN, max=2, min=0, offset=0}, i-signal-in-i-pdu=MasterUwbXcpResponse}, transmission-mode-false-timing=cyclic-timing=time-period=0.1, transmission-mode-true-timing=cyclic-timing=time-period=0.1
          signal MasterUwbXcpResponse: start 7, 64 bit, big-endian, base-type=uint64
      frame MasterNm: id 0x470, from MasterMcu, frame-length=8, can-addressing-mode=STANDARD
        carries pdu MasterNm: packing-byte-order=little-endian, start-position=0, update-indication-bit-position=-1
        nm pdu MasterNm: length=8, nm-data-information=false, nm-vote-information=false
          signal PMMode: start 40, 8 bit, little-endian, init-value=0, base-type=uint8, compu {raw=phys for phys 0..255, 0=STOPPED, 1=SEARCHING, 2=LOCALISING, 3=STANDBY, 4=INVALID}  # PK System Power State"
          signal AutosarNMControl: start 0, 8 bit, little-endian, base-type=uint8  # SWS_CanNm_0045
      frame TesterPhysical_Req_PK_Anchor4: id 0x704, from MasterMcu, frame-length=64, can-addressing-mode=STANDARD
        carries pdu TesterPhysical_Req_PK_Anchor4: start-position=7, update-indication-bit-position=-1
        n pdu TesterPhysical_Req_PK_Anchor4: length=64
      frame TesterFunctional_Req_PK: id 0x750, from MasterMcu, frame-length=8, can-addressing-mode=STANDARD
        carries pdu TesterFunctional_Req_PK: start-position=7, update-indication-bit-position=-1
        n pdu TesterFunctional_Req_PK: length=8
      frame TesterPhysical_Req_PK_Anchor3: id 0x703, from MasterMcu, frame-length=64, can-addressing-mode=STANDARD
        carries pdu TesterPhysical_Req_PK_Anchor3: start-position=7, update-indication-bit-position=-1
        n pdu TesterPhysical_Req_PK_Anchor3: length=64
      frame TesterPhysical_Req_PK_Anchor2: id 0x702, from MasterMcu, frame-length=64, can-addressing-mode=STANDARD
        carries pdu TesterPhysical_Req_PK_Anchor2: start-position=7, update-indication-bit-position=-1
        n pdu TesterPhysical_Req_PK_Anchor2: length=64
      frame TesterPhysical_Req_PK_Anchor1: id 0x701, from MasterMcu, frame-length=64, can-addressing-mode=STANDARD
        carries pdu TesterPhysical_Req_PK_Anchor1: start-position=7, update-indication-bit-position=-1
        n pdu TesterPhysical_Req_PK_Anchor1: length=64
      frame Anchor3TpUwb_M2A: id 0x443, from MasterMcu, frame-length=64, can-addressing-mode=STANDARD
        carries pdu Anchor3TpUwb_M2A: start-position=7, update-indication-bit-position=-1
        n pdu Anchor3TpUwb_M2A: length=64
      frame Anchor2TpUwb_M2A: id 0x442, from MasterMcu, frame-length=64, can-addressing-mode=STANDARD
        carries pdu Anchor2TpUwb_M2A: start-position=7, update-indication-bit-position=-1
        n pdu Anchor2TpUwb_M2A: length=64
      frame Anchor9TpBle_M2A: id 0x409, from MasterMcu, frame-length=64, can-addressing-mode=STANDARD
        carries pdu Anchor9TpBle_M2A: start-position=7, update-indication-bit-position=-1
        n pdu Anchor9TpBle_M2A: length=64
      frame Anchor8TpBle_M2A: id 0x408, from MasterMcu, frame-length=64, can-addressing-mode=STANDARD
        carries pdu Anchor8TpBle_M2A: start-position=7, update-indication-bit-position=-1
        n pdu Anchor8TpBle_M2A: length=64
      frame Anchor9TpUwb_M2A: id 0x449, from MasterMcu, frame-length=64, can-addressing-mode=STANDARD
        carries pdu Anchor9TpUwb_M2A: start-position=7, update-indication-bit-position=-1
        n pdu Anchor9TpUwb_M2A: length=64
      frame Anchor7TpBle_M2A: id 0x407, from MasterMcu, frame-length=64, can-addressing-mode=STANDARD
        carries pdu Anchor7TpBle_M2A: start-position=7, update-indication-bit-position=-1
        n pdu Anchor7TpBle_M2A: length=64
      frame Anchor8TpUwb_M2A: id 0x448, from MasterMcu, frame-length=64, can-addressing-mode=STANDARD
        carries pdu Anchor8TpUwb_M2A: start-position=7, update-indication-bit-position=-1
        n pdu Anchor8TpUwb_M2A: length=64
      frame Anchor6TpBle_M2A: id 0x406, from MasterMcu, frame-length=64, can-addressing-mode=STANDARD
        carries pdu Anchor6TpBle_M2A: start-position=7, update-indication-bit-position=-1
        n pdu Anchor6TpBle_M2A: length=64
      frame Anchor7TpUwb_M2A: id 0x447, from MasterMcu, frame-length=64, can-addressing-mode=STANDARD
        carries pdu Anchor7TpUwb_M2A: start-position=7, update-indication-bit-position=-1
        n pdu Anchor7TpUwb_M2A: length=64
      frame Anchor6TpUwb_M2A: id 0x446, from MasterMcu, frame-length=64, can-addressing-mode=STANDARD
        carries pdu Anchor6TpUwb_M2A: start-position=7, update-indication-bit-position=-1
        n pdu Anchor6TpUwb_M2A: length=64
      frame Anchor5TpUwb_M2A: id 0x445, from MasterMcu, frame-length=64, can-addressing-mode=STANDARD
        carries pdu Anchor5TpUwb_M2A: start-position=7, update-indication-bit-position=-1
        n pdu Anchor5TpUwb_M2A: length=64
      frame Anchor4TpUwb_M2A: id 0x444, from MasterMcu, frame-length=64, can-addressing-mode=STANDARD
        carries pdu Anchor4TpUwb_M2A: start-position=7, update-indication-bit-position=-1
        n pdu Anchor4TpUwb_M2A: length=64
      frame TesterPhysical_Req_PK_Anchor8: id 0x708, from MasterMcu, frame-length=64, can-addressing-mode=STANDARD
        carries pdu TesterPhysical_Req_PK_Anchor8: start-position=7, update-indication-bit-position=-1
        n pdu TesterPhysical_Req_PK_Anchor8: length=64
      frame MasterBleXcpResponse: id 0x620, from MasterMcu, frame-length=8, can-addressing-mode=STANDARD
        carries pdu MasterBleXcpResponse: packing-byte-order=big-endian, start-position=7, update-indication-bit-position=-1
        pdu MasterBleXcpResponse: length=8, transmission-mode-condition{data-filter={data-filter-type=NEW-IS-WITHIN, max=2, min=0, offset=0}, i-signal-in-i-pdu=MasterBleXcpResponse}
          signal MasterBleXcpResponse: start 7, 64 bit, big-endian, base-type=uint64
      frame Anchor5TpBle_M2A: id 0x405, from MasterMcu, frame-length=64, can-addressing-mode=STANDARD
        carries pdu Anchor5TpBle_M2A: start-position=7, update-indication-bit-position=-1
        n pdu Anchor5TpBle_M2A: length=64
      frame Anchor4TpBle_M2A: id 0x404, from MasterMcu, frame-length=64, can-addressing-mode=STANDARD
        carries pdu Anchor4TpBle_M2A: start-position=7, update-indication-bit-position=-1
        n pdu Anchor4TpBle_M2A: length=64
      frame Anchor3TpBle_M2A: id 0x403, from MasterMcu, frame-length=64, can-addressing-mode=STANDARD
        carries pdu Anchor3TpBle_M2A: start-position=7, update-indication-bit-position=-1
        n pdu Anchor3TpBle_M2A: length=64
      frame Anchor2TpBle_M2A: id 0x402, from MasterMcu, frame-length=64, can-addressing-mode=STANDARD
        carries pdu Anchor2TpBle_M2A: start-position=7, update-indication-bit-position=-1
        n pdu Anchor2TpBle_M2A: length=64
      frame MasterHi_M2A: id 0x170, from MasterMcu, frame-length=64, can-addressing-mode=STANDARD
        carries pdu MasterHi_M2A: packing-byte-order=little-endian, start-position=0, update-indication-bit-position=-1
        pdu MasterHi_M2A: length=64, transmission-mode-condition{data-filter={data-filter-type=NEW-IS-WITHIN, max=0, min=0, offset=0}, i-signal-in-i-pdu=MasterHi_M2A_Payload}
          signal MasterHi_M2A_Payload: start 0, 16 bit, little-endian, base-type=sint16
      frame Anchor1TpBle_M2A: id 0x401, from MasterMcu, frame-length=64, can-addressing-mode=STANDARD
        carries pdu Anchor1TpBle_M2A: start-position=7, update-indication-bit-position=-1
        n pdu Anchor1TpBle_M2A: length=64
      frame Anchor1TpUwb_M2A: id 0x441, from MasterMcu, frame-length=64, can-addressing-mode=STANDARD
        carries pdu Anchor1TpUwb_M2A: start-position=7, update-indication-bit-position=-1
        n pdu Anchor1TpUwb_M2A: length=64
      frame TimeSync_Master: id 0x50, from MasterMcu, frame-length=16, can-addressing-mode=STANDARD
        carries pdu TimeSync_Master: packing-byte-order=little-endian, start-position=0, update-indication-bit-position=-1
        pdu TimeSync_Master: length=16, transmission-mode-false-timing=cyclic-timing={time-offset=0.0, time-period=5.0}, transmission-mode-true-timing=cyclic-timing={time-offset=0.0, time-period=5.0}
          transmission-mode-conditions:
            {data-filter={data-filter-type=NEW-IS-WITHIN, max=16777215, min=0, offset=0}, i-signal-in-i-pdu=MAC_Sync}
            {data-filter={data-filter-type=NEW-IS-WITHIN, max=4294967295, min=0, offset=0}, i-signal-in-i-pdu=SyncTimeSec_Master}
            {data-filter={data-filter-type=ALWAYS, max=255, min=0, offset=0}, i-signal-in-i-pdu=UserByte0_Master}
            {data-filter={data-filter-type=ALWAYS, max=15, min=0, offset=0}, i-signal-in-i-pdu=ScSync_Master}
            {data-filter={data-filter-type=ALWAYS, max=15, min=0, offset=0}, i-signal-in-i-pdu=TimeDomain_Sync_Master}
            {data-filter={data-filter-type=ALWAYS, max=255, min=0, offset=0}, i-signal-in-i-pdu=CrcSync_Master}
            {data-filter={data-filter-type=ALWAYS, max=255, min=0, offset=0}, i-signal-in-i-pdu=Type_Sync_Master}
          signal MAC_Sync: start 104, 24 bit, little-endian, init-value=0, base-type=uint32, compu {raw=phys for phys 0..16777215}, transfer-property=PENDING  # SysST_1458"
          signal SyncTimeSec_Master: start 32, 32 bit, little-endian, init-value=0, base-type=uint32, compu {raw=phys for phys 0..4294967295}, transfer-property=PENDING  # SysST_1455"
          signal UserByte0_Master: start 24, 8 bit, little-endian, base-type=uint8, transfer-property=PENDING  # SysST_1454
          signal ScSync_Master: start 16, 4 bit, little-endian, base-type=uint8, transfer-property=PENDING  # SysST_1453
          signal TimeDomain_Sync_Master: start 20, 4 bit, little-endian, base-type=uint8, transfer-property=PENDING  # SysST_1452
          signal CrcSync_Master: start 8, 8 bit, little-endian, base-type=uint8, transfer-property=PENDING  # SysST_1451
          signal Type_Sync_Master: start 0, 8 bit, little-endian, init-value=32, base-type=uint8, compu {raw=phys for phys 0..255}, transfer-property=PENDING  # SysST_1450"
      frame TesterPhysical_Res_PK_MasterBle: id 0x720, from MasterMcu, frame-length=64, can-addressing-mode=STANDARD
        carries pdu TesterPhysical_Res_PK_MasterBle: start-position=7, update-indication-bit-position=-1
        n pdu TesterPhysical_Res_PK_MasterBle: length=64
      frame TesterPhysical_Req_PK_Anchor9: id 0x709, from MasterMcu, frame-length=64, can-addressing-mode=STANDARD
        carries pdu TesterPhysical_Req_PK_Anchor9: start-position=7, update-indication-bit-position=-1
        n pdu TesterPhysical_Req_PK_Anchor9: length=64
      pdu triggering PduTrig_Anchor{1..9}TpBle_A2M_Tp: pdu=Anchor{1..9}TpBle_A2M_Tp, to MasterMcu
      pdu triggering PduTrig_Anchor1TpBle_M2A_Tp: pdu=Anchor1TpBle_M2A_Tp, from MasterMcu
      pdu triggering PduTrig_Anchor{3..9}TpBle_M2A_Tp: pdu=Anchor{3..9}TpBle_M2A_Tp, from MasterMcu
      pdu triggering PduTrig_Anchor{1..9}TpUwb_A2M_Tp: pdu=Anchor{1..9}TpUwb_A2M_Tp, to MasterMcu
      pdu triggering PduTrig_Anchor{1..9}TpUwb_M2A_Tp: pdu=Anchor{1..9}TpUwb_M2A_Tp, from MasterMcu
      pdu triggering PduTrig_Anchor2TpBle_M2A_Tp: pdu=Anchor2TpBle_M2A_Tp, from MasterMcu
      pdu triggering PduTrig_TesterFunctional_Req_PK_Tp: pdu=TesterFunctional_Req_PK_Tp, from MasterMcu
      pdu triggering PduTrig_TesterPhysical_Req_PK_Anchor{1..9}_Tp: pdu=TesterPhysical_Req_PK_Anchor{1..9}_Tp, from MasterMcu
      pdu triggering PduTrig_TesterPhysical_Res_PK_Anchor{1..9}_Tp: pdu=TesterPhysical_Res_PK_Anchor{1..9}_Tp, to MasterMcu
      pdu triggering PduTrig_TesterPhysical_Res_PK_MasterBle_Tp: pdu=TesterPhysical_Res_PK_MasterBle_Tp, from MasterMcu
      pdu triggering PduTrig_TesterPhysical_Req_PK_MasterBle_Tp: pdu=TesterPhysical_Req_PK_MasterBle_Tp, to MasterMcu
  can tp config PK_BB_MasterEcu_Tp: communication-cluster=Can_Network_PK_BB, can-tp-ecu=MasterMcu
    can tp address CanTPAddress_TpCfg_PK_BB: tp-address=0
    can tp channel TP_CHN_Can_PK_BB: channel-mode=FULL-DUPLEX-MODE
    tp-connections:
      addressing-format=STANDARD, can-tp-channel=TP_CHN_Can_PK_BB, data-pdu=Anchor9TpBle_A2M, flow-control-pdu=Anchor9TpBle_M2A, max-block-size=15, padding-activation=false, receiver=CanTpNode_MasterMcu, ta-type=PHYSICAL, timeout-br=0.1, timeout-bs=1.0, timeout-cr=1.0, timeout-cs=1.0, tp-sdu=Anchor9TpBle_A2M_Tp, transmit-cancellation=false, transmitter=CanTpNode_Anchor9
      addressing-format=STANDARD, can-tp-channel=TP_CHN_Can_PK_BB, data-pdu=Anchor8TpBle_A2M, flow-control-pdu=Anchor8TpBle_M2A, max-block-size=15, padding-activation=false, receiver=CanTpNode_MasterMcu, ta-type=PHYSICAL, timeout-br=0.1, timeout-bs=1.0, timeout-cr=1.0, timeout-cs=1.0, tp-sdu=Anchor8TpBle_A2M_Tp, transmit-cancellation=false, transmitter=CanTpNode_Anchor8
      addressing-format=STANDARD, can-tp-channel=TP_CHN_Can_PK_BB, data-pdu=Anchor7TpBle_A2M, flow-control-pdu=Anchor7TpBle_M2A, max-block-size=15, padding-activation=false, receiver=CanTpNode_MasterMcu, ta-type=PHYSICAL, timeout-br=0.1, timeout-bs=1.0, timeout-cr=1.0, timeout-cs=1.0, tp-sdu=Anchor7TpBle_A2M_Tp, transmit-cancellation=false, transmitter=CanTpNode_Anchor7
      addressing-format=STANDARD, can-tp-channel=TP_CHN_Can_PK_BB, data-pdu=Anchor6TpBle_A2M, flow-control-pdu=Anchor6TpBle_M2A, max-block-size=15, padding-activation=false, receiver=CanTpNode_MasterMcu, ta-type=PHYSICAL, timeout-br=0.1, timeout-bs=1.0, timeout-cr=1.0, timeout-cs=1.0, tp-sdu=Anchor6TpBle_A2M_Tp, transmit-cancellation=false, transmitter=CanTpNode_Anchor6
      addressing-format=STANDARD, can-tp-channel=TP_CHN_Can_PK_BB, data-pdu=Anchor5TpBle_A2M, flow-control-pdu=Anchor5TpBle_M2A, max-block-size=15, padding-activation=false, receiver=CanTpNode_MasterMcu, ta-type=PHYSICAL, timeout-br=0.1, timeout-bs=1.0, timeout-cr=1.0, timeout-cs=1.0, tp-sdu=Anchor5TpBle_A2M_Tp, transmit-cancellation=false, transmitter=CanTpNode_Anchor5
      addressing-format=STANDARD, can-tp-channel=TP_CHN_Can_PK_BB, data-pdu=Anchor4TpBle_A2M, flow-control-pdu=Anchor4TpBle_M2A, max-block-size=15, padding-activation=false, receiver=CanTpNode_MasterMcu, ta-type=PHYSICAL, timeout-br=0.1, timeout-bs=1.0, timeout-cr=1.0, timeout-cs=1.0, tp-sdu=Anchor4TpBle_A2M_Tp, transmit-cancellation=false, transmitter=CanTpNode_Anchor4
      addressing-format=STANDARD, can-tp-channel=TP_CHN_Can_PK_BB, data-pdu=Anchor3TpBle_A2M, flow-control-pdu=Anchor3TpBle_M2A, max-block-size=15, padding-activation=false, receiver=CanTpNode_MasterMcu, ta-type=PHYSICAL, timeout-br=0.1, timeout-bs=1.0, timeout-cr=1.0, timeout-cs=1.0, tp-sdu=Anchor3TpBle_A2M_Tp, transmit-cancellation=false, transmitter=CanTpNode_Anchor3
      addressing-format=STANDARD, can-tp-channel=TP_CHN_Can_PK_BB, data-pdu=Anchor2TpBle_A2M, flow-control-pdu=Anchor2TpBle_M2A, max-block-size=15, padding-activation=false, receiver=CanTpNode_MasterMcu, ta-type=PHYSICAL, timeout-br=0.1, timeout-bs=1.0, timeout-cr=1.0, timeout-cs=1.0, tp-sdu=Anchor2TpBle_A2M_Tp, transmit-cancellation=false, transmitter=CanTpNode_Anchor2
      addressing-format=STANDARD, can-tp-channel=TP_CHN_Can_PK_BB, data-pdu=Anchor1TpBle_A2M, flow-control-pdu=Anchor1TpBle_M2A, max-block-size=15, padding-activation=false, receiver=CanTpNode_MasterMcu, ta-type=PHYSICAL, timeout-br=0.1, timeout-bs=1.0, timeout-cr=1.0, timeout-cs=1.0, tp-sdu=Anchor1TpBle_A2M_Tp, transmit-cancellation=false, transmitter=CanTpNode_Anchor1
      addressing-format=STANDARD, can-tp-channel=TP_CHN_Can_PK_BB, data-pdu=TesterPhysical_Req_PK_MasterBle, flow-control-pdu=TesterPhysical_Res_PK_MasterBle, max-block-size=15, padding-activation=false, receiver=CanTpNode_MasterMcu, ta-type=PHYSICAL, timeout-br=0.1, timeout-bs=1.0, timeout-cr=1.0, timeout-cs=1.0, tp-sdu=TesterPhysical_Req_PK_MasterBle_Tp, transmit-cancellation=false, transmitter=CanTpNode_MasterBle
      addressing-format=STANDARD, can-tp-channel=TP_CHN_Can_PK_BB, data-pdu=TesterPhysical_Res_PK_Anchor5, flow-control-pdu=TesterPhysical_Req_PK_Anchor5, max-block-size=15, padding-activation=false, receiver=CanTpNode_MasterMcu, ta-type=PHYSICAL, timeout-br=0.1, timeout-bs=1.0, timeout-cr=1.0, timeout-cs=1.0, tp-sdu=TesterPhysical_Res_PK_Anchor5_Tp, transmit-cancellation=false, transmitter=CanTpNode_Anchor5
      addressing-format=STANDARD, can-tp-channel=TP_CHN_Can_PK_BB, data-pdu=TesterPhysical_Res_PK_Anchor4, flow-control-pdu=TesterPhysical_Req_PK_Anchor4, max-block-size=15, padding-activation=false, receiver=CanTpNode_MasterMcu, ta-type=PHYSICAL, timeout-br=0.1, timeout-bs=1.0, timeout-cr=1.0, timeout-cs=1.0, tp-sdu=TesterPhysical_Res_PK_Anchor4_Tp, transmit-cancellation=false, transmitter=CanTpNode_Anchor4
      addressing-format=STANDARD, can-tp-channel=TP_CHN_Can_PK_BB, data-pdu=TesterPhysical_Res_PK_Anchor3, flow-control-pdu=TesterPhysical_Req_PK_Anchor3, max-block-size=15, padding-activation=false, receiver=CanTpNode_MasterMcu, ta-type=PHYSICAL, timeout-br=0.1, timeout-bs=1.0, timeout-cr=1.0, timeout-cs=1.0, tp-sdu=TesterPhysical_Res_PK_Anchor3_Tp, transmit-cancellation=false, transmitter=CanTpNode_Anchor3
      addressing-format=STANDARD, can-tp-channel=TP_CHN_Can_PK_BB, data-pdu=TesterPhysical_Res_PK_Anchor2, flow-control-pdu=TesterPhysical_Req_PK_Anchor2, max-block-size=15, padding-activation=false, receiver=CanTpNode_MasterMcu, ta-type=PHYSICAL, timeout-br=0.1, timeout-bs=1.0, timeout-cr=1.0, timeout-cs=1.0, tp-sdu=TesterPhysical_Res_PK_Anchor2_Tp, transmit-cancellation=false, transmitter=CanTpNode_Anchor2
      addressing-format=STANDARD, can-tp-channel=TP_CHN_Can_PK_BB, data-pdu=TesterPhysical_Res_PK_Anchor1, flow-control-pdu=TesterPhysical_Req_PK_Anchor1, max-block-size=15, padding-activation=false, receiver=CanTpNode_MasterMcu, ta-type=PHYSICAL, timeout-br=0.1, timeout-bs=1.0, timeout-cr=1.0, timeout-cs=1.0, tp-sdu=TesterPhysical_Res_PK_Anchor1_Tp, transmit-cancellation=false, transmitter=CanTpNode_Anchor1
      addressing-format=STANDARD, can-tp-channel=TP_CHN_Can_PK_BB, data-pdu=Anchor1TpUwb_A2M, flow-control-pdu=Anchor1TpUwb_M2A, max-block-size=15, padding-activation=false, receiver=CanTpNode_MasterMcu, ta-type=PHYSICAL, timeout-br=0.1, timeout-bs=1.0, timeout-cr=1.0, timeout-cs=1.0, tp-sdu=Anchor1TpUwb_A2M_Tp, transmit-cancellation=false, transmitter=CanTpNode_Anchor1
      addressing-format=STANDARD, can-tp-channel=TP_CHN_Can_PK_BB, data-pdu=TesterPhysical_Res_PK_Anchor9, flow-control-pdu=TesterPhysical_Req_PK_Anchor9, max-block-size=15, padding-activation=false, receiver=CanTpNode_MasterMcu, ta-type=PHYSICAL, timeout-br=0.1, timeout-bs=1.0, timeout-cr=1.0, timeout-cs=1.0, tp-sdu=TesterPhysical_Res_PK_Anchor9_Tp, transmit-cancellation=false, transmitter=CanTpNode_Anchor9
      addressing-format=STANDARD, can-tp-channel=TP_CHN_Can_PK_BB, data-pdu=TesterPhysical_Res_PK_Anchor8, flow-control-pdu=TesterPhysical_Req_PK_Anchor8, max-block-size=15, padding-activation=false, receiver=CanTpNode_MasterMcu, ta-type=PHYSICAL, timeout-br=0.1, timeout-bs=1.0, timeout-cr=1.0, timeout-cs=1.0, tp-sdu=TesterPhysical_Res_PK_Anchor8_Tp, transmit-cancellation=false, transmitter=CanTpNode_Anchor8
      addressing-format=STANDARD, can-tp-channel=TP_CHN_Can_PK_BB, data-pdu=TesterPhysical_Res_PK_Anchor7, flow-control-pdu=TesterPhysical_Req_PK_Anchor7, max-block-size=15, padding-activation=false, receiver=CanTpNode_MasterMcu, ta-type=PHYSICAL, timeout-br=0.1, timeout-bs=1.0, timeout-cr=1.0, timeout-cs=1.0, tp-sdu=TesterPhysical_Res_PK_Anchor7_Tp, transmit-cancellation=false, transmitter=CanTpNode_Anchor7
      addressing-format=STANDARD, can-tp-channel=TP_CHN_Can_PK_BB, data-pdu=TesterPhysical_Res_PK_Anchor6, flow-control-pdu=TesterPhysical_Req_PK_Anchor6, max-block-size=15, padding-activation=false, receiver=CanTpNode_MasterMcu, ta-type=PHYSICAL, timeout-br=0.1, timeout-bs=1.0, timeout-cr=1.0, timeout-cs=1.0, tp-sdu=TesterPhysical_Res_PK_Anchor6_Tp, transmit-cancellation=false, transmitter=CanTpNode_Anchor6
      addressing-format=STANDARD, can-tp-channel=TP_CHN_Can_PK_BB, data-pdu=Anchor9TpUwb_A2M, flow-control-pdu=Anchor9TpUwb_M2A, max-block-size=15, padding-activation=false, receiver=CanTpNode_MasterMcu, ta-type=PHYSICAL, timeout-br=0.1, timeout-bs=1.0, timeout-cr=1.0, timeout-cs=1.0, tp-sdu=Anchor9TpUwb_A2M_Tp, transmit-cancellation=false, transmitter=CanTpNode_Anchor9
      addressing-format=STANDARD, can-tp-channel=TP_CHN_Can_PK_BB, data-pdu=Anchor8TpUwb_A2M, flow-control-pdu=Anchor8TpUwb_M2A, max-block-size=15, padding-activation=false, receiver=CanTpNode_MasterMcu, ta-type=PHYSICAL, timeout-br=0.1, timeout-bs=1.0, timeout-cr=1.0, timeout-cs=1.0, tp-sdu=Anchor8TpUwb_A2M_Tp, transmit-cancellation=false, transmitter=CanTpNode_Anchor8
      addressing-format=STANDARD, can-tp-channel=TP_CHN_Can_PK_BB, data-pdu=Anchor7TpUwb_A2M, flow-control-pdu=Anchor7TpUwb_M2A, max-block-size=15, padding-activation=false, receiver=CanTpNode_MasterMcu, ta-type=PHYSICAL, timeout-br=0.1, timeout-bs=1.0, timeout-cr=1.0, timeout-cs=1.0, tp-sdu=Anchor7TpUwb_A2M_Tp, transmit-cancellation=false, transmitter=CanTpNode_Anchor7
      addressing-format=STANDARD, can-tp-channel=TP_CHN_Can_PK_BB, data-pdu=Anchor6TpUwb_A2M, flow-control-pdu=Anchor6TpUwb_M2A, max-block-size=15, padding-activation=false, receiver=CanTpNode_MasterMcu, ta-type=PHYSICAL, timeout-br=0.1, timeout-bs=1.0, timeout-cr=1.0, timeout-cs=1.0, tp-sdu=Anchor6TpUwb_A2M_Tp, transmit-cancellation=false, transmitter=CanTpNode_Anchor6
      addressing-format=STANDARD, can-tp-channel=TP_CHN_Can_PK_BB, data-pdu=Anchor5TpUwb_A2M, flow-control-pdu=Anchor5TpUwb_M2A, max-block-size=15, padding-activation=false, receiver=CanTpNode_MasterMcu, ta-type=PHYSICAL, timeout-br=0.1, timeout-bs=1.0, timeout-cr=1.0, timeout-cs=1.0, tp-sdu=Anchor5TpUwb_A2M_Tp, transmit-cancellation=false, transmitter=CanTpNode_Anchor5
      addressing-format=STANDARD, can-tp-channel=TP_CHN_Can_PK_BB, data-pdu=Anchor4TpUwb_A2M, flow-control-pdu=Anchor4TpUwb_M2A, max-block-size=15, padding-activation=false, receiver=CanTpNode_MasterMcu, ta-type=PHYSICAL, timeout-br=0.1, timeout-bs=1.0, timeout-cr=1.0, timeout-cs=1.0, tp-sdu=Anchor4TpUwb_A2M_Tp, transmit-cancellation=false, transmitter=CanTpNode_Anchor4
      addressing-format=STANDARD, can-tp-channel=TP_CHN_Can_PK_BB, data-pdu=Anchor3TpUwb_A2M, flow-control-pdu=Anchor3TpUwb_M2A, max-block-size=15, padding-activation=false, receiver=CanTpNode_MasterMcu, ta-type=PHYSICAL, timeout-br=0.1, timeout-bs=1.0, timeout-cr=1.0, timeout-cs=1.0, tp-sdu=Anchor3TpUwb_A2M_Tp, transmit-cancellation=false, transmitter=CanTpNode_Anchor3
      addressing-format=STANDARD, can-tp-channel=TP_CHN_Can_PK_BB, data-pdu=Anchor2TpUwb_A2M, flow-control-pdu=Anchor2TpUwb_M2A, max-block-size=15, padding-activation=false, receiver=CanTpNode_MasterMcu, ta-type=PHYSICAL, timeout-br=0.1, timeout-bs=1.0, timeout-cr=1.0, timeout-cs=1.0, tp-sdu=Anchor2TpUwb_A2M_Tp, transmit-cancellation=false, transmitter=CanTpNode_Anchor2
      addressing-format=STANDARD, can-tp-channel=TP_CHN_Can_PK_BB, data-pdu=TesterPhysical_Req_PK_Anchor7, flow-control-pdu=TesterPhysical_Res_PK_Anchor7, max-block-size=15, padding-activation=false, receiver=CanTpNode_Anchor7, ta-type=PHYSICAL, timeout-br=0.1, timeout-bs=1.0, timeout-cr=1.0, timeout-cs=1.0, tp-sdu=TesterPhysical_Req_PK_Anchor7_Tp, transmit-cancellation=false, transmitter=CanTpNode_MasterMcu
      addressing-format=STANDARD, can-tp-channel=TP_CHN_Can_PK_BB, data-pdu=TesterPhysical_Req_PK_Anchor6, flow-control-pdu=TesterPhysical_Res_PK_Anchor6, max-block-size=15, padding-activation=true, receiver=CanTpNode_Anchor6, ta-type=PHYSICAL, timeout-br=0.1, timeout-bs=1.0, timeout-cr=1.0, timeout-cs=1.0, tp-sdu=TesterPhysical_Req_PK_Anchor6_Tp, transmit-cancellation=false, transmitter=CanTpNode_MasterMcu
      addressing-format=STANDARD, can-tp-channel=TP_CHN_Can_PK_BB, data-pdu=TesterPhysical_Req_PK_Anchor5, flow-control-pdu=TesterPhysical_Res_PK_Anchor5, max-block-size=15, padding-activation=false, receiver=CanTpNode_Anchor5, ta-type=PHYSICAL, timeout-br=0.1, timeout-bs=1.0, timeout-cr=1.0, timeout-cs=1.0, tp-sdu=TesterPhysical_Req_PK_Anchor5_Tp, transmit-cancellation=false, transmitter=CanTpNode_MasterMcu
      addressing-format=STANDARD, can-tp-channel=TP_CHN_Can_PK_BB, data-pdu=TesterPhysical_Req_PK_Anchor4, flow-control-pdu=TesterPhysical_Res_PK_Anchor4, max-block-size=15, padding-activation=false, receiver=CanTpNode_Anchor4, ta-type=PHYSICAL, timeout-br=0.1, timeout-bs=1.0, timeout-cr=1.0, timeout-cs=1.0, tp-sdu=TesterPhysical_Req_PK_Anchor4_Tp, transmit-cancellation=false, transmitter=CanTpNode_MasterMcu
      addressing-format=STANDARD, can-tp-channel=TP_CHN_Can_PK_BB, data-pdu=TesterFunctional_Req_PK, max-block-size=15, padding-activation=false, receiver=CanTpNode_Tester, ta-type=FUNCTIONAL, timeout-br=0.1, timeout-bs=1.0, timeout-cr=1.0, timeout-cs=1.0, tp-sdu=TesterFunctional_Req_PK_Tp, transmit-cancellation=false, transmitter=CanTpNode_MasterMcu
      addressing-format=STANDARD, can-tp-channel=TP_CHN_Can_PK_BB, data-pdu=TesterPhysical_Req_PK_Anchor3, flow-control-pdu=TesterPhysical_Res_PK_Anchor3, max-block-size=15, padding-activation=false, receiver=CanTpNode_Anchor3, ta-type=PHYSICAL, timeout-br=0.1, timeout-bs=1.0, timeout-cr=1.0, timeout-cs=1.0, tp-sdu=TesterPhysical_Req_PK_Anchor3_Tp, transmit-cancellation=false, transmitter=CanTpNode_MasterMcu
      addressing-format=STANDARD, can-tp-channel=TP_CHN_Can_PK_BB, data-pdu=TesterPhysical_Req_PK_Anchor2, flow-control-pdu=TesterPhysical_Res_PK_Anchor2, max-block-size=15, padding-activation=false, receiver=CanTpNode_Anchor2, ta-type=PHYSICAL, timeout-br=0.1, timeout-bs=1.0, timeout-cr=1.0, timeout-cs=1.0, tp-sdu=TesterPhysical_Req_PK_Anchor2_Tp, transmit-cancellation=false, transmitter=CanTpNode_MasterMcu
      addressing-format=STANDARD, can-tp-channel=TP_CHN_Can_PK_BB, data-pdu=TesterPhysical_Req_PK_Anchor1, flow-control-pdu=TesterPhysical_Res_PK_Anchor1, max-block-size=15, padding-activation=false, receiver=CanTpNode_Anchor1, ta-type=PHYSICAL, timeout-br=0.1, timeout-bs=1.0, timeout-cr=1.0, timeout-cs=1.0, tp-sdu=TesterPhysical_Req_PK_Anchor1_Tp, transmit-cancellation=false, transmitter=CanTpNode_MasterMcu
      addressing-format=STANDARD, can-tp-channel=TP_CHN_Can_PK_BB, data-pdu=Anchor3TpUwb_M2A, flow-control-pdu=Anchor3TpUwb_A2M, max-block-size=15, padding-activation=false, receiver=CanTpNode_Anchor3, ta-type=PHYSICAL, timeout-br=0.1, timeout-bs=1.0, timeout-cr=1.0, timeout-cs=1.0, tp-sdu=Anchor3TpUwb_M2A_Tp, transmit-cancellation=false, transmitter=CanTpNode_MasterMcu
      addressing-format=STANDARD, can-tp-channel=TP_CHN_Can_PK_BB, data-pdu=Anchor2TpUwb_M2A, flow-control-pdu=Anchor2TpUwb_A2M, max-block-size=15, padding-activation=false, receiver=CanTpNode_Anchor2, ta-type=PHYSICAL, timeout-br=0.1, timeout-bs=1.0, timeout-cr=1.0, timeout-cs=1.0, tp-sdu=Anchor2TpUwb_M2A_Tp, transmit-cancellation=false, transmitter=CanTpNode_MasterMcu
      addressing-format=STANDARD, can-tp-channel=TP_CHN_Can_PK_BB, data-pdu=Anchor9TpBle_M2A, flow-control-pdu=Anchor9TpBle_A2M, max-block-size=15, padding-activation=false, receiver=CanTpNode_Anchor9, ta-type=PHYSICAL, timeout-br=0.1, timeout-bs=1.0, timeout-cr=1.0, timeout-cs=1.0, tp-sdu=Anchor9TpBle_M2A_Tp, transmit-cancellation=false, transmitter=CanTpNode_MasterMcu
      addressing-format=STANDARD, can-tp-channel=TP_CHN_Can_PK_BB, data-pdu=Anchor8TpBle_M2A, flow-control-pdu=Anchor8TpBle_A2M, max-block-size=15, padding-activation=false, receiver=CanTpNode_Anchor8, ta-type=PHYSICAL, timeout-br=0.1, timeout-bs=1.0, timeout-cr=1.0, timeout-cs=1.0, tp-sdu=Anchor8TpBle_M2A_Tp, transmit-cancellation=false, transmitter=CanTpNode_MasterMcu
      addressing-format=STANDARD, can-tp-channel=TP_CHN_Can_PK_BB, data-pdu=Anchor9TpUwb_M2A, flow-control-pdu=Anchor9TpUwb_A2M, max-block-size=15, padding-activation=false, receiver=CanTpNode_Anchor9, ta-type=PHYSICAL, timeout-br=0.1, timeout-bs=1.0, timeout-cr=1.0, timeout-cs=1.0, tp-sdu=Anchor9TpUwb_M2A_Tp, transmit-cancellation=false, transmitter=CanTpNode_MasterMcu
      addressing-format=STANDARD, can-tp-channel=TP_CHN_Can_PK_BB, data-pdu=Anchor7TpBle_M2A, flow-control-pdu=Anchor7TpBle_A2M, max-block-size=15, padding-activation=false, receiver=CanTpNode_Anchor7, ta-type=PHYSICAL, timeout-br=0.1, timeout-bs=1.0, timeout-cr=1.0, timeout-cs=1.0, tp-sdu=Anchor7TpBle_M2A_Tp, transmit-cancellation=false, transmitter=CanTpNode_MasterMcu
      addressing-format=STANDARD, can-tp-channel=TP_CHN_Can_PK_BB, data-pdu=Anchor8TpUwb_M2A, flow-control-pdu=Anchor8TpUwb_A2M, max-block-size=15, padding-activation=false, receiver=CanTpNode_Anchor8, ta-type=PHYSICAL, timeout-br=0.1, timeout-bs=1.0, timeout-cr=1.0, timeout-cs=1.0, tp-sdu=Anchor8TpUwb_M2A_Tp, transmit-cancellation=false, transmitter=CanTpNode_MasterMcu
      addressing-format=STANDARD, can-tp-channel=TP_CHN_Can_PK_BB, data-pdu=Anchor6TpBle_M2A, flow-control-pdu=Anchor6TpBle_A2M, max-block-size=15, padding-activation=false, receiver=CanTpNode_Anchor6, ta-type=PHYSICAL, timeout-br=0.1, timeout-bs=1.0, timeout-cr=1.0, timeout-cs=1.0, tp-sdu=Anchor6TpBle_M2A_Tp, transmit-cancellation=false, transmitter=CanTpNode_MasterMcu
      addressing-format=STANDARD, can-tp-channel=TP_CHN_Can_PK_BB, data-pdu=Anchor7TpUwb_M2A, flow-control-pdu=Anchor7TpUwb_A2M, max-block-size=15, padding-activation=false, receiver=CanTpNode_Anchor7, ta-type=PHYSICAL, timeout-br=0.1, timeout-bs=1.0, timeout-cr=1.0, timeout-cs=1.0, tp-sdu=Anchor7TpUwb_M2A_Tp, transmit-cancellation=false, transmitter=CanTpNode_MasterMcu
      addressing-format=STANDARD, can-tp-channel=TP_CHN_Can_PK_BB, data-pdu=Anchor6TpUwb_M2A, flow-control-pdu=Anchor6TpUwb_A2M, max-block-size=15, padding-activation=false, receiver=CanTpNode_Anchor6, ta-type=PHYSICAL, timeout-br=0.1, timeout-bs=1.0, timeout-cr=1.0, timeout-cs=1.0, tp-sdu=Anchor6TpUwb_M2A_Tp, transmit-cancellation=false, transmitter=CanTpNode_MasterMcu
      addressing-format=STANDARD, can-tp-channel=TP_CHN_Can_PK_BB, data-pdu=Anchor5TpUwb_M2A, flow-control-pdu=Anchor5TpUwb_A2M, max-block-size=15, padding-activation=false, receiver=CanTpNode_Anchor5, ta-type=PHYSICAL, timeout-br=0.1, timeout-bs=1.0, timeout-cr=1.0, timeout-cs=1.0, tp-sdu=Anchor5TpUwb_M2A_Tp, transmit-cancellation=false, transmitter=CanTpNode_MasterMcu
      addressing-format=STANDARD, can-tp-channel=TP_CHN_Can_PK_BB, data-pdu=Anchor4TpUwb_M2A, flow-control-pdu=Anchor4TpUwb_A2M, max-block-size=15, padding-activation=false, receiver=CanTpNode_Anchor4, ta-type=PHYSICAL, timeout-br=0.1, timeout-bs=1.0, timeout-cr=1.0, timeout-cs=1.0, tp-sdu=Anchor4TpUwb_M2A_Tp, transmit-cancellation=false, transmitter=CanTpNode_MasterMcu
      addressing-format=STANDARD, can-tp-channel=TP_CHN_Can_PK_BB, data-pdu=TesterPhysical_Req_PK_Anchor8, flow-control-pdu=TesterPhysical_Res_PK_Anchor8, max-block-size=15, padding-activation=false, receiver=CanTpNode_Anchor8, ta-type=PHYSICAL, timeout-br=0.1, timeout-bs=1.0, timeout-cr=1.0, timeout-cs=1.0, tp-sdu=TesterPhysical_Req_PK_Anchor8_Tp, transmit-cancellation=false, transmitter=CanTpNode_MasterMcu
      addressing-format=STANDARD, can-tp-channel=TP_CHN_Can_PK_BB, data-pdu=Anchor5TpBle_M2A, flow-control-pdu=Anchor5TpBle_A2M, max-block-size=15, padding-activation=false, receiver=CanTpNode_Anchor5, ta-type=PHYSICAL, timeout-br=0.1, timeout-bs=1.0, timeout-cr=1.0, timeout-cs=1.0, tp-sdu=Anchor5TpBle_M2A_Tp, transmit-cancellation=false, transmitter=CanTpNode_MasterMcu
      addressing-format=STANDARD, can-tp-channel=TP_CHN_Can_PK_BB, data-pdu=Anchor4TpBle_M2A, flow-control-pdu=Anchor4TpBle_A2M, max-block-size=15, padding-activation=false, receiver=CanTpNode_Anchor4, ta-type=PHYSICAL, timeout-br=0.1, timeout-bs=1.0, timeout-cr=1.0, timeout-cs=1.0, tp-sdu=Anchor4TpBle_M2A_Tp, transmit-cancellation=false, transmitter=CanTpNode_MasterMcu
      addressing-format=STANDARD, can-tp-channel=TP_CHN_Can_PK_BB, data-pdu=Anchor3TpBle_M2A, flow-control-pdu=Anchor3TpBle_A2M, max-block-size=15, padding-activation=false, receiver=CanTpNode_Anchor3, ta-type=PHYSICAL, timeout-br=0.1, timeout-bs=1.0, timeout-cr=1.0, timeout-cs=1.0, tp-sdu=Anchor3TpBle_M2A_Tp, transmit-cancellation=false, transmitter=CanTpNode_MasterMcu
      addressing-format=STANDARD, can-tp-channel=TP_CHN_Can_PK_BB, data-pdu=Anchor2TpBle_M2A, flow-control-pdu=Anchor2TpBle_A2M, max-block-size=15, padding-activation=false, receiver=CanTpNode_Anchor2, ta-type=PHYSICAL, timeout-br=0.1, timeout-bs=1.0, timeout-cr=1.0, timeout-cs=1.0, tp-sdu=Anchor2TpBle_M2A_Tp, transmit-cancellation=false, transmitter=CanTpNode_MasterMcu
      addressing-format=STANDARD, can-tp-channel=TP_CHN_Can_PK_BB, data-pdu=Anchor1TpBle_M2A, flow-control-pdu=Anchor1TpBle_A2M, max-block-size=15, padding-activation=false, receiver=CanTpNode_Anchor1, ta-type=PHYSICAL, timeout-br=0.1, timeout-bs=1.0, timeout-cr=1.0, timeout-cs=1.0, tp-sdu=Anchor1TpBle_M2A_Tp, transmit-cancellation=false, transmitter=CanTpNode_MasterMcu
      addressing-format=STANDARD, can-tp-channel=TP_CHN_Can_PK_BB, data-pdu=Anchor1TpUwb_M2A, flow-control-pdu=Anchor1TpUwb_A2M, max-block-size=15, padding-activation=false, receiver=CanTpNode_Anchor1, ta-type=PHYSICAL, timeout-br=0.1, timeout-bs=1.0, timeout-cr=1.0, timeout-cs=1.0, tp-sdu=Anchor1TpUwb_M2A_Tp, transmit-cancellation=false, transmitter=CanTpNode_MasterMcu
      addressing-format=STANDARD, can-tp-channel=TP_CHN_Can_PK_BB, data-pdu=TesterPhysical_Res_PK_MasterBle, flow-control-pdu=TesterPhysical_Req_PK_MasterBle, max-block-size=15, padding-activation=false, receiver=CanTpNode_MasterBle, ta-type=PHYSICAL, timeout-br=0.1, timeout-bs=1.0, timeout-cr=1.0, timeout-cs=1.0, tp-sdu=TesterPhysical_Res_PK_MasterBle_Tp, transmit-cancellation=false, transmitter=CanTpNode_MasterMcu
      addressing-format=STANDARD, can-tp-channel=TP_CHN_Can_PK_BB, data-pdu=TesterPhysical_Req_PK_Anchor9, flow-control-pdu=TesterPhysical_Res_PK_Anchor9, max-block-size=15, padding-activation=false, receiver=CanTpNode_Anchor9, ta-type=PHYSICAL, timeout-br=0.1, timeout-bs=1.0, timeout-cr=1.0, timeout-cs=1.0, tp-sdu=TesterPhysical_Req_PK_Anchor9_Tp, transmit-cancellation=false, transmitter=CanTpNode_MasterMcu
    12 x can tp node:
      CanTpNode_MasterMcu: connector=Conn_Can_PK_BB_MasterEcu, max-fc-wait=0, st-min=0.0, timeout-ar=0.1, timeout-as=0.1, tp-address=CanTPAddress_TpCfg_PK_BB
      CanTpNode_Anchor{1..9}
      CanTpNode_MasterBle
      CanTpNode_Tester
package /PK_BB_Can_Network/Pkg_Nm
  nm config NmConfig_PK_BB
    can nm cluster CanNmMode_MasterMcu_PK_BB:
      communication-cluster=Can_Network_PK_BB
      nm-channel-id=1
      nm-channel-sleep-master=false
      nm-synchronizing-network=false
      nm-busload-reduction-active=false
      nm-car-wake-up-filter-enabled=false
      nm-car-wake-up-rx-enabled=false
      nm-cbv-position=1
      nm-channel-active=false
      nm-immediate-nm-cycle-time=0.1
      nm-immediate-nm-transmissions=0
      nm-message-timeout-time=0.1
      nm-msg-cycle-time=0.2
      nm-network-timeout=1.0
      nm-nid-position=0
      nm-remote-sleep-indication-time=0.0
      nm-user-data-length=6
      nm-wait-bus-sleep-time=0.75
      can nm node CanNm_MasterMcu_PK_BB: controller=Can_Network_PK_BB_MasterEcu, nm-if-ecu=NmEcu_MasterMcu, nm-node-id=1, nm-passive-mode-enabled=false, rx-nm-pdu=[Anchor7Nm, Anchor6Nm, Anchor5Nm, Anchor4Nm, Anchor3Nm, Anchor2Nm, Anchor1Nm, Anchor9Nm, Anchor8Nm], tx-nm-pdu=MasterNm, nm-range-config={lower-can-id=1280, upper-can-id=1289}
    nm-if-ecus:
      nm ecu NmEcu_MasterMcu:
        bus-specific-nm-ecu=can-nm-ecu=nm-repeat-msg-indication-enabled=false
        ecu-instance=MasterMcu
        nm-bus-synchronization-enabled=false
        nm-com-control-enabled=false
        nm-coordinator=nm-node=CanNm_MasterMcu_PK_BB
        nm-cycletime-main-function=0.1
        nm-multiple-channels-enabled=false
        nm-node-detection-enabled=false
        nm-node-id-enabled=false
        nm-passive-mode-enabled=false
        nm-pdu-rx-indication-enabled=false
        nm-remote-sleep-ind-enabled=false
        nm-repeat-msg-ind-enabled=false
        nm-state-change-ind-enabled=false
        nm-user-data-enabled=false
package /PK_BB_Can_Network/Pkg_Ecu
  ecu instance MasterMcu: associated-com-i-pdu-group=[MasterMcu_PK_BB_Rx, MasterMcu_PK_BB_Tx, MasterMcu_PK_BB_Rx, MasterMcu_PK_BB_Tx], can-tp-address=CanTPAddress_TpCfg_PK_BB, com-configuration-gw-time-base=0.005, com-configuration-rx-time-base=0.01, com-configuration-tx-time-base=0.01, sleep-mode-supported=false, wake-up-over-bus-supported=false
    can communication controller Can_Network_PK_BB_MasterEcu: can-controller-attributes=can-controller-configuration={sync-jump-width=3, time-seg-1=3, time-seg-2=3}
    can communication connector Conn_Can_PK_BB_MasterEcu: comm-controller=Can_Network_PK_BB_MasterEcu
